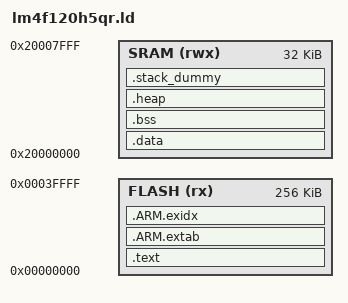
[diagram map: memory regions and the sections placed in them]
_stack_size = 4K;

MEMORY
{
    FLASH (rx) : ORIGIN = 0x00000000, LENGTH = 256K
    SRAM (rwx) : ORIGIN = 0x20000000, LENGTH = 32K
}

SECTIONS
{
    .text :
    {
        _text = .;
        KEEP(*(.isr_vector))
        *(.text*)
        *(.init)
        *(.fini)


        *(.rodata*)
        *(.eh_frame*)
        
    } > FLASH

    .ARM.extab : 
    {
        *(.ARM.extab* .gnu.linkonce.armextab.*)
    } > FLASH

    __exidx_start = .;
    .ARM.exidx :
    {
        *(.ARM.exidx* .gnu.linkonce.armexidx.*)
    } > FLASH
    __exidx_end = .;

    __etext = .;
    
    .data : AT(__etext)
    {
        __data_start__ = .;
        *(vtable)
        *(.data*)

        . = ALIGN(4);
        /* preinit data */
        PROVIDE_HIDDEN (__preinit_array_start = .);
        *(.preinit_array)
        PROVIDE_HIDDEN (__preinit_array_end = .);

        . = ALIGN(4);
        /* init data */
        PROVIDE_HIDDEN (__init_array_start = .);
        *(SORT(.init_array.*))
        *(.init_array)
        PROVIDE_HIDDEN (__init_array_end = .);


        . = ALIGN(4);
        /* finit data */
        PROVIDE_HIDDEN (__fini_array_start = .);
        *(SORT(.fini_array.*))
        *(.fini_array)
        PROVIDE_HIDDEN (__fini_array_end = .);

        *(.jcr)
        . = ALIGN(4);
        /* All data end */
        __data_end__ = .;

    } > SRAM

    .bss :
    {
        . = ALIGN(4);
        __bss_start__ = .;
        *(.bss*)
        *(COMMON)
        . = ALIGN(4);
        __bss_end__ = .;
    } > SRAM
    
    .heap (COPY):
    {
        __end__ = .;
        end = __end__;
        *(.heap*)
        __HeapLimit = .;
    } > SRAM

    PROVIDE(__heap_end__ = ORIGIN(SRAM) + LENGTH(SRAM) - _stack_size);
    
    /* .stack_dummy section doesn't contains any symbols. It is only
     * used for linker to calculate size of stack sections, and assign
     * values to stack symbols later */
    .stack_dummy (COPY):
    {
        *(.stack*)
    } > SRAM

    /* Set stack top to end of SRAM, and stack limit move down by
     * size of stack_dummy section */
    __StackTop = ORIGIN(SRAM) + LENGTH(SRAM);
    __StackLimit = __StackTop - SIZEOF(.stack_dummy);

    PROVIDE(__stack = __StackTop);

    /* Check if data + heap + stack exceeds RAM limit */
    ASSERT(__StackLimit >= __HeapLimit, "region RAM overflowed with stack")
}
